# PCIE0_DAT register map
Vendor: Texas Instruments
Registers are 32-bit, read-write, reset 0x0 unless marked. A register's access mark holds for its fields unless they carry their own. Offsets are as the file gives them; [hi:lo] are bit positions; {n}, {i} and the like mark numbered series.

## PCIE0_DAT (part 2 of 6)
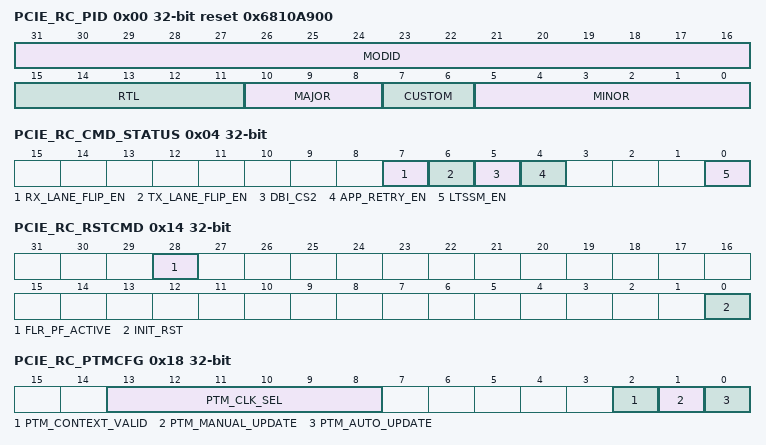
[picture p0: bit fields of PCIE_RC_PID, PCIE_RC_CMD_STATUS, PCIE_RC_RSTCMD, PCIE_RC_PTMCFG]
0x00 PCIE_RC_PID ro reset 0x6810A900 — Peripheral Version and ID Register
  [31:16] MODID — Module ID of the Peripheral
  [15:11] RTL — RTL Version Number
  [10:8] MAJOR — Major Revision Code
  [7:6] CUSTOM — Custom Code
  [5:0] MINOR — Minor Revision Code
0x04 PCIE_RC_CMD_STATUS access per field — Command Status Register
  [7] RX_LANE_FLIP_EN rw — Set to enable manual reversal for RX lanes. This drives the rx_lane_flip_en input of the PCIe core
  [6] TX_LANE_FLIP_EN rw — Set to enable manual reversal for TX lanes. This drives the tx_lane_flip_en input of the PCIe core
  [5] DBI_CS2 rw — Set to enable writing to BAR mask registers that are overlaid on BAR registers.
  [4] APP_RETRY_EN rw — Application Request Retry Enable. Setting this bit will enable all incoming PCIe transactions to be returned with a retry response. This feature can be used if initialization can take longer than PCIe stipulated time frame.
  [0] LTSSM_EN rw — Link Training Enable. Setting this bit will enable LTSSM in PCI Express Core and link negotiation with link partner will begin.
0x14 PCIE_RC_RSTCMD access not given — Reset Command and Status Register
  [28] FLR_PF_ACTIVE ro — Function-level reset for physical function active. 1 - FLR for Physical function 0 is active
  [0] INIT_RST — Write one to initiate a downstream hot reset sequence on downstream (access RW1S)
0x18 PCIE_RC_PTMCFG access not given — PTM Config register
  [13:8] PTM_CLK_SEL rw — Select ptm_local_clk bit input to CPTS. 0 will select ptm_local_clk[0], 1 will select ptm_local_clk[1] ... 63 will select ptm_local_clk[63]
  [2] PTM_CONTEXT_VALID ro — '1' indicates PTM context is valid-EP only
  [1] PTM_MANUAL_UPDATE — Write '1' to enable PTM transaction.EP only. EP will initiate one PTM transaction when this field is updated. Always reads '0' (access RW1S)
  [0] PTM_AUTO_UPDATE rw — Write '1' to enable PTM auto-update-EP only. EP will automatically initiate PTM transaction every 10ms
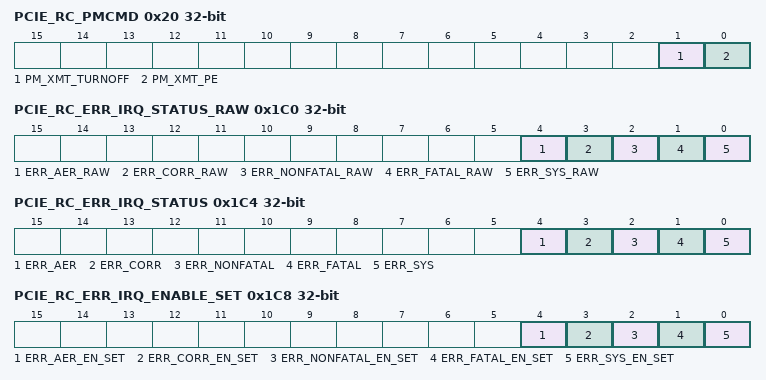
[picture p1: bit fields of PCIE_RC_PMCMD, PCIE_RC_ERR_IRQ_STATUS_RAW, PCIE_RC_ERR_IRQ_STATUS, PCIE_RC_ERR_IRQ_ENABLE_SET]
0x20 PCIE_RC_PMCMD access not given — Power Management Command Register
  [1] PM_XMT_TURNOFF — Write one to transmit a PM_TURNOFF message. Reads zero. Applicable in RC mode only. (access RW1S)
  [0] PM_XMT_PE — Write one to transmit a PM_PME message for Physical Function 0. Reads zero. Applicable to EP mode only. (access RW1S)
0x50 PCIE_RC_IRQ_EOI access per field — End of Interrupt Register
  [3:0] EOI rw — EOI for interrupts. Write to indicate end-of-interrupt for the respective interrupt. EOI value has to be the following as indicated below to toggle the interrupts in the various interrupt registers EOI = 0 for LEGACY_A_IRQ, EOI = 1 for LEGACY_B_IRQ, EOI = 2 for LEGACY_C_IRQ, EOI = 3 for LEGACY_D_IRQ, EOI = 4 for MMR0_IRQ, EOI = 5 for MMR1_IRQ, EOI = 6 for MMR2_IRQ, EOI = 7 for MMR3_IRQ, EOI = 8 for MMR4_IRQ, EOI = 9 for MMR5_IRQ, EOI = 10 for MMR6_IRQ, EOI = 11 for MMR7_IRQ, EOI = 12 for ERR_IRQ, EOI = 13 for PMRST_IRQ, EOI = 14 for PTM_IRQ
0x54 PCIE_RC_MMR_IRQ — Memory Mapped Interrupt IRQ Register
  [30:0] MMR_IRQ — This register is not used in RC mode.
0x64 PCIE_RC_LEGACY_IRQ_SET access not given — Legacy Interrupt Request Set Register
  [0] LEGACY_IRQ_SET_0 — Write one to generate assert legacy PCI interrupt message for Physical Function0. On read, a one indicates currently asserted interrupt. (access RW1S)
0x68 PCIE_RC_LEGACY_IRQ_CLR access not given — Legacy Interrupt Request Clear Register
  [0] LEGACY_IRQ_CLR_0 — Write one to generate legacy PCI deassert interrupt message for Physical Function0. If MSI is disabled, legacy interrupt deassert message will be generated. On read, a one indicates currently asserted interrupt. (access RW1C)
0x6C PCIE_RC_LEGACY_IRQ_STATUS ro — Legacy Interrupt Status Register
  [0] LEGACY_IRQ_STATUS_0 — Indicates whether legacy PCI interrupt for physical function 0 is asserted or not
{0x70+4i} PCIE_RC_GPR{i} (i=0..3) — General Purpose {i} Register
  [31:0] GENERIC{i} — Generic Info field {i}
{0x100+0x10*i} PCIE_RC_MMR{i}_IRQ_STATUS_RAW access not given (i=0..6) — MMR {i} Interrupt Raw Status Register
  [3:0] MMR{i}_IRQ_STATUS_RAW — Each bit indicates raw status of MMR vectors ({i+24}, {i+16}, {i+8}, {i}) associated with the bit. Typically, writes to this register are only done for debug purposes. (access RW1S)
{0x104+0x10*i} PCIE_RC_MMR{i}_IRQ_STATUS access not given (i=0..7) — MMR {i} Interrupt Status Register
  [3:0] MMR{i}_IRQ_STATUS — Each bit indicates status of MMR vector ({i+24}, {i+16}, {i+8}, {i}) associated with the bit. Each of the bits can be written with one to clear the respective interrupt status bit. (access RW1C)
{0x108+0x10*i} PCIE_RC_MMR{i}_IRQ_ENABLE_SET access not given (i=0..7) — MMR {i} Interrupt Enable Set Register
  [3:0] MMR{i}_IRQ_EN_SET — Each bit, when written to, enables the MMR interrupt ({i+24}, {i+16}, {i+8}, {i}) associated with the bit (access RW1S)
{0x10C+0x10*i} PCIE_RC_MMR{i}_IRQ_ENABLE_CLR access not given (i=0..7) — MMR {i} Interrupt Enable Clear Register
  [3:0] MMR{i}_IRQ_EN_CLR — Each bit, when written to, disables the MMR interrupt ({i+24}, {i+16}, {i+8}, {i}) associated with the bit (access RW1C)
0x170 PCIE_RC_MMR7_IRQ_STATUS_RAW access not given — MMR 7 Interrupt Raw Status Register
  [3:0] MMR7_IRQ_STATUS_RAW — (access RW1S)
0x180 PCIE_RC_LEGACY_A_IRQ_STATUS_RAW access not given — Legacy A Raw Interrupt Status Register
  [0] INTA_RAW — Legacy Interrupt A raw status. RC mode only (access RW1S)
0x184 PCIE_RC_LEGACY_A_IRQ_STATUS access not given — Legacy A Raw Interrupt Status Register
  [0] INTA — Legacy Interrupt A status. Set when interrupt is active. Write one to clear the interrupt event. RC mode only (access RW1C)
0x188 PCIE_RC_LEGACY_A_IRQ_ENABLE_SET access not given — Legacy A Interrupt Enable Set Register
  [0] INTA_EN_SET — Legacy Interrupt A enable. Set to enable the interrupt. On read, one/zero means interrupt is enabled/disabled. (access RW1S)
0x18C PCIE_RC_LEGACY_A_IRQ_ENABLE_CLR access not given — Legacy A Interrupt Enable Clear Register
  [0] INTA_EN_CLR — Legacy Interrupt A disable. Set to disable the interrupt. Read one/zero means interrupt is enabled/disabled. (access RW1C)
0x190 PCIE_RC_LEGACY_B_IRQ_STATUS_RAW access not given — Legacy B Raw Interrupt Status Register
  [0] INTB_RAW — Legacy Interrupt B raw status. RC mode only (access RW1S)
0x194 PCIE_RC_LEGACY_B_IRQ_STATUS access not given — Legacy B Interrupt Status Register
  [0] INTA — Legacy Interrupt B status. Set when interrupt is active. Write one to clear the interrupt event. RC mode only. (access RW1C)
0x198 PCIE_RC_LEGACY_B_IRQ_ENABLE_SET access not given — Legacy B Interrupt Enable Set Register
  [0] INTB_EN_SET — Legacy Interrupt B enable. Set to enable the interrupt. On read, one/zero means interrupt is enabled/disabled. (access RW1S)
0x19C PCIE_RC_LEGACY_B_IRQ_ENABLE_CLR access not given — Legacy B Interrupt Enable Clear Register
  [0] INTB_EN_CLR — Legacy Interrupt B disable. Set to disable the interrupt. Read one/zero means interrupt is enabled/disabled. (access RW1C)
0x1A0 PCIE_RC_LEGACY_C_IRQ_STATUS_RAW access not given — Legacy C Raw Interrupt Status Register
  [0] INTC_RAW — Legacy Interrupt C raw status. RC mode only (access RW1S)
0x1A4 PCIE_RC_LEGACY_C_IRQ_STATUS access not given — Legacy C Interrupt Status Register
  [0] INTA — Legacy Interrupt C status. Set when interrupt is active. Write one to clear the interrupt event. RC mode only (access RW1C)
0x1A8 PCIE_RC_LEGACY_C_IRQ_ENABLE_SET access not given — Legacy C Interrupt Enable Set Register
  [0] INTC_EN_SET — Legacy Interrupt C enable. Set to enable the interrupt. On read, one/zero means interrupt is enabled/disabled. (access RW1S)
0x1AC PCIE_RC_LEGACY_C_IRQ_ENABLE_CLR access not given — Legacy C Interrupt Enable Clear Register
  [0] INTC_EN_CLR — Legacy Interrupt C disable. Set to disable the interrupt. Read one/zero means interrupt is enabled/disabled. (access RW1C)
0x1B0 PCIE_RC_LEGACY_D_IRQ_STATUS_RAW access not given — Legacy D Raw Interrupt Status Register
  [0] INTD_RAW — Legacy Interrupt D raw status. RC mode only (access RW1S)
0x1B4 PCIE_RC_LEGACY_D_IRQ_STATUS access not given — Legacy D Interrupt Status Register
  [0] INTA — Legacy Interrupt D status. Set when interrupt is active. Write one to clear the interrupt event. RC mode only (access RW1C)
0x1B8 PCIE_RC_LEGACY_D_IRQ_ENABLE_SET access not given — Legacy D Interrupt Enable Set Register
  [0] INTD_EN_SET — Legacy Interrupt D enable. Set to enable the interrupt. On read, one/zero means interrupt is enabled/disabled. (access RW1S)
0x1BC PCIE_RC_LEGACY_D_IRQ_ENABLE_CLR access not given — Legacy D Interrupt Enable Clear Register
  [0] INTD_EN_CLR — Legacy Interrupt D disable. Set to disable the interrupt. Read one/zero means interrupt is enabled/disabled. (access RW1C)
0x1C0 PCIE_RC_ERR_IRQ_STATUS_RAW access not given — Raw ERR Interrupt Status Register
  [4] ERR_AER_RAW — AER MSI error raw status. This interrupt is generated due to the assertion of the cfg_aer_rc_err_int or the cfg_aer_err_msi output of the PCIe controller core. (access RW1S)
  [3] ERR_CORR_RAW — Correctable error raw status. This interrupt is generated due to the assertion of the radm_correctable_err output of the PCIe controller core. (access RW1S)
  [2] ERR_NONFATAL_RAW — Nonfatal error raw status. This interrupt is generated due to the assertion of the radm_nonfatal_err output of the PCIe controller core. (access RW1S)
  [1] ERR_FATAL_RAW — Fatal error raw status. This interrupt is generated due to the assertion of the radm_fatal_err output of the PCIe controller core. (access RW1S)
  [0] ERR_SYS_RAW — System Error (FATAL, NONFATAL or CORRECTABLE error) raw status. This interrupt is generated due to the assertion of the cfg_sys_err_rc output of the PCIe controller core. (access RW1S)
0x1C4 PCIE_RC_ERR_IRQ_STATUS access not given
  [4] ERR_AER — AER MSI error status. This interrupt is generated due to the assertion of the cfg_aer_rc_err_int or the cfg_aer_err_msi output of the PCIe controller core. Write one to clear (access RW1C)
  [3] ERR_CORR — Correctable error status. This interrupt is generated due to the assertion of the radm_correctable_err output of the PCIe controller core. Write one to clear (access RW1C)
  [2] ERR_NONFATAL — Nonfatal error status. This interrupt is generated due to the assertion of the radm_nonfatal_err output of the PCIe controller core. Write one to clear. (access RW1C)
  [1] ERR_FATAL — Fatal error status. This interrupt is generated due to the assertion of the radm_fatal_err output of the PCIe controller core. Write one to clear. (access RW1C)
  [0] ERR_SYS — System Error (FATAL, NONFATAL or CORRECTABLE error). This interrupt is generated due to the assertion of the cfg_sys_err_rc output of the PCIe controller core. Write one to clear. (access RW1C)
0x1C8 PCIE_RC_ERR_IRQ_ENABLE_SET access not given
  [4] ERR_AER_EN_SET — AER MSI error interrupt enable. Set to enable. On read, one/zero means enabled/disabled respectively (access RW1S)
  [3] ERR_CORR_EN_SET — Correctable error interrupt enable. Set to enable the interrupt. On read, one/zero means interrupt is enabled/disabled. (access RW1S)
  [2] ERR_NONFATAL_EN_SET — Nonfatal error interrupt enable. Set to enable the interrupt. On read, one/zero means interrupt is enabled/disabled. (access RW1S)
  [1] ERR_FATAL_EN_SET — Fatal error interrupt enable. Set to enable the interrupt. On read, one/zero means interrupt is enabled/disabled. (access RW1S)
  [0] ERR_SYS_EN_SET — System Error (FATAL, NONFATAL or CORRECTABLE error) interrupt enable. Set to enable the interrupt. On read, one/zero means interrupt is enabled/disabled. (access RW1S)
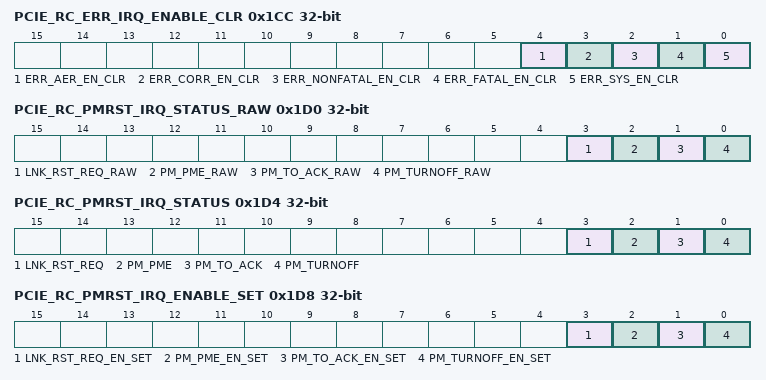
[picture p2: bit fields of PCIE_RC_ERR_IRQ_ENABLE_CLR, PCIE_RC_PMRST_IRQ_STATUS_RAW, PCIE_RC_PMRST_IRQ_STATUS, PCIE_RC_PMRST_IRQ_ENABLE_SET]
0x1CC PCIE_RC_ERR_IRQ_ENABLE_CLR access not given
  [4] ERR_AER_EN_CLR — AER MSI error interrupt disable. Set to disable. On read, one/zero means enabled/disabled respectively. (access RW1C)
  [3] ERR_CORR_EN_CLR — Correctable error interrupt disable. Set to disable the interrupt. Read one/zero means interrupt is enabled/disabled. (access RW1C)
  [2] ERR_NONFATAL_EN_CLR — Nonfatal error interrupt disable. Set to disable the interrupt. Read one/zero means interrupt is enabled/disabled. (access RW1C)
  [1] ERR_FATAL_EN_CLR — Fatal error interrupt disable. Set to disable the interrupt. Read one/zero means interrupt is enabled/disabled. (access RW1C)
  [0] ERR_SYS_EN_CLR — System Error (FATAL, NONFATAL or CORRECTABLE error) interrupt disable. Set to disable the interrupt. Read one/zero means interrupt is enabled/disabled. (access RW1C)
0x1D0 PCIE_RC_PMRST_IRQ_STATUS_RAW access not given — Power Management and Reset Interrupt Raw Status Register
  [3] LNK_RST_REQ_RAW — Link Request Reset interrupt raw status (access RW1S)
  [2] PM_PME_RAW — Power Management PME message received interrupt raw status (access RW1S)
  [1] PM_TO_ACK_RAW — Power Management ACK received interrupt raw status (access RW1S)
  [0] PM_TURNOFF_RAW — Power Management Turnoff message received raw status (access RW1S)
0x1D4 PCIE_RC_PMRST_IRQ_STATUS access not given — Power Management and Reset Interrupt Status Register
  [3] LNK_RST_REQ — Link Request Reset interrupt status. Write one to clear (access RW1C)
  [2] PM_PME — Power Management PME message received interrupt status. Write one to clear. (access RW1C)
  [1] PM_TO_ACK — Power Management ACK received interrupt status. Write one to clear. (access RW1C)
  [0] PM_TURNOFF — Power Management Turnoff message received status. Write one to clear. (access RW1C)
0x1D8 PCIE_RC_PMRST_IRQ_ENABLE_SET access not given — Power Management and Reset Interrupt Enable Set Register
  [3] LNK_RST_REQ_EN_SET — Link Request Reset interrupt enable. Set to enable the interrupt. Read one/zero means interrupt is enabled/disabled. (access RW1S)
  [2] PM_PME_EN_SET — Power Management PME message received interrupt enable. Set to enable the interrupt. Read one/zero means interrupt is enabled/disabled. (access RW1S)
  [1] PM_TO_ACK_EN_SET — Power Management ACK received interrupt enable. Set to enable the interrupt. Read one/zero means interrupt is enabled/disabled. (access RW1S)
  [0] PM_TURNOFF_EN_SET — Power Management Turnoff message received enable. Set to enable the interrupt. Read one/zero means interrupt is enabled/disabled. (access RW1S)
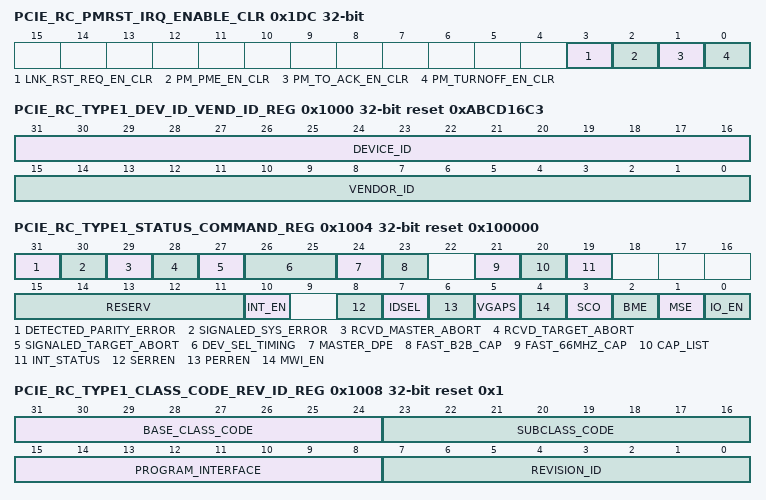
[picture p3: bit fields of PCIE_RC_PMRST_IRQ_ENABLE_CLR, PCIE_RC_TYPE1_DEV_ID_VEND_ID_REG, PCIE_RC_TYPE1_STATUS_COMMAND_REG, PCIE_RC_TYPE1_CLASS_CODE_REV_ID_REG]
0x1DC PCIE_RC_PMRST_IRQ_ENABLE_CLR access not given — Power Management and Reset Interrupt Enable Clear Register
  [3] LNK_RST_REQ_EN_CLR — Link Request Reset interrupt disable. Set to disable the interrupt. Read one/zero means interrupt is enabled/disabled. (access RW1C)
  [2] PM_PME_EN_CLR — Power Management PME message received interrupt disable. Set to disable the interrupt. Read one/zero means interrupt is enabled/disabled. (access RW1C)
  [1] PM_TO_ACK_EN_CLR — Power Management ACK received interrupt disable. Set to disable the interrupt. Read one/zero means interrupt is enabled/disabled. (access RW1C)
  [0] PM_TURNOFF_EN_CLR — Power Management Turnoff message received disable. Set to disable the interrupt. Read one/zero means interrupt is enabled/disabled (access RW1C)
0x1E0 PCIE_RC_PTM_IRQ_STATUS_RAW access not given — Precision Time Measurement Raw Status Register
  [0] PTM_CLK_UPDATED_RAW — Precision Time Measurement interrupt raw status (access RW1S)
0x1E4 PCIE_RC_PTM_IRQ_STATUS access not given — Precision Time Measurement Status Register
  [0] PTM_CLK_UPDATED — Precision Time Measurement interrupt status (access RW1C)
0x1E8 PCIE_RC_PTM_IRQ_ENABLE_SET access not given — Precision Time Measurement Enable Set Register
  [0] PTM_CLK_UPDATED_EN_SET — Precision Time Measurement interrupt enable set. Write one to set (access RW1S)
0x1EC PCIE_RC_PTM_IRQ_ENABLE_CLR access not given — Precision Time Measurement Enable Clear Register
  [0] PTM_CLK_UPDATED_EN_CLR — Precision Time Measurement interrupt enable clear. Write one to clear (access RW1C)
0x1000 PCIE_RC_TYPE1_DEV_ID_VEND_ID_REG ro reset 0xABCD16C3 — Device ID and Vendor ID Register. For a description of this standard PCIe register, see the PCI Express Specification.
  [31:16] DEVICE_ID — Device ID - Vendor Assigned Device Identifier For a description of this standard PCIe register field, see the PCI Express Specification Note: The access attributes of this field are as follows: - Dbi: if [DBI_RO_WR_EN == 1] then R/W[sticky] else R[sticky] Note: This register field is sticky
  [15:0] VENDOR_ID — Vendor ID - PCI-SIG assigned Manufacturer Identifier For a description of this standard PCIe register field, see the PCI Express Specification Note: The access attributes of this field are as follows: - Dbi: if [DBI_RO_WR_EN == 1] then R/W[sticky] else R[sticky] Note: This register field is sticky
0x1004 PCIE_RC_TYPE1_STATUS_COMMAND_REG access not given reset 0x100000 — Command and Status Register. For a description of this standard PCIe register, see the PCI Express Specification.
  [31] DETECTED_PARITY_ERROR — Poisoned TLP received by function on Primary Side For a description of this standard PCIe register field, see the PCI Express Specification (access RW1C)
  [30] SIGNALED_SYS_ERROR — Fatal or Non-Fatal Error Message sent by function For a description of this standard PCIe register field, see the PCI Express Specification (access RW1C)
  [29] RCVD_MASTER_ABORT — Unsupported request completion status received on Primary Side For a description of this standard PCIe register field, see the PCI Express Specification (access RW1C)
  [28] RCVD_TARGET_ABORT — Completer Abort received on Primary Side For a description of this standard PCIe register field, see the PCI Express Specification (access RW1C)
  [27] SIGNALED_TARGET_ABORT — Primary Side Completer Abort Error For a description of this standard PCIe register field, see the PCI Express Specification (access RW1C)
  [26:25] DEV_SEL_TIMING ro — Device Select Timing For a description of this standard PCIe register field, see the PCI Express Specification
  [24] MASTER_DPE — Controls poisoned Completion and Request error reporting For a description of this standard PCIe register field, see the PCI Express Specification (access RW1C)
  [23] FAST_B2B_CAP ro — Fast Back to Back Transaction Capable and Enable For a description of this standard PCIe register field, see the PCI Express Specification
  [21] FAST_66MHZ_CAP ro — PCI 66MHz Capability For a description of this standard PCIe register field, see the PCI Express Specification
  [20] CAP_LIST ro — Extended Capability For a description of this standard PCIe register field, see the PCI Express Specification
  [19] INT_STATUS ro — Emulation interrupt pending internally in function For a description of this standard PCIe register field, see the PCI Express Specification
  [15:11] RESERV ro — Reserved For a description of this standard PCIe register field, see the PCI Express Specification
  [10] INT_EN rw — Interrupt Disable Controls generation of interrupts by an internal function For a description of this standard PCIe register field, see the PCI Express Specification
  [8] SERREN rw — Enables Error Reporting and Forwarding For a description of this standard PCIe register field, see the PCI Express Specification
  [7] IDSEL ro — IDSEL Stepping/Wait Cycle Control For a description of this standard PCIe register field, see the PCI Express Specification
  [6] PERREN rw — Parity Error Response Controls Logging of Poisoned TLPs For a description of this standard PCIe register field, see the PCI Express Specification
  [5] VGAPS ro — VGA Palette Snoop For a description of this standard PCIe register field, see the PCI Express Specification
  [4] MWI_EN ro — Memory Write and Invalidate For a description of this standard PCIe register field, see the PCI Express Specification
  [3] SCO ro — Special Cycle Enable For a description of this standard PCIe register field, see the PCI Express Specification
  [2] BME rw — Bus Master Enable Controls Forwarding of Memory and I/O Requests For a description of this standard PCIe register field, see the PCI Express Specification
  [1] MSE rw — Enables Memory Access Response For a description of this standard PCIe register field, see the PCI Express Specification You cannot write to this register if your configuration has no MEM bars that is, the internal signal has_mem_bar=0 Note: The access attributes of this field are as follows: - Dbi: !has_mem_bar ? RO : RW
  [0] IO_EN rw — Enables IO Access Response For a description of this standard PCIe register field, see the PCI Express Specification You cannot write to this register if your configuration has no IO bars that is, the internal signal has_io_bar=0 Note: The access attributes of this field are as follows: - Dbi: !has_io_bar ? RO : RW
0x1008 PCIE_RC_TYPE1_CLASS_CODE_REV_ID_REG ro reset 0x1 — Class Code and Revision ID Register. For a description of this standard PCIe register, see the PCI Express Specification.
  [31:24] BASE_CLASS_CODE — Base Class Code to represent Device Type For a description of this standard PCIe register field, see the PCI Express Specification Note: The access attributes of this field are as follows: - Dbi: if [DBI_RO_WR_EN == 1] then R/W[sticky] else R[sticky] Note: This register field is sticky
  [23:16] SUBCLASS_CODE — Subclass Code to represent Device Type For a description of this standard PCIe register field, see the PCI Express Specification Note: The access attributes of this field are as follows: - Dbi: if [DBI_RO_WR_EN == 1] then R/W[sticky] else R[sticky] Note: This register field is sticky
  [15:8] PROGRAM_INTERFACE — Class Code Programming Interface For a description of this standard PCIe register field, see the PCI Express Specification Note: The access attributes of this field are as follows: - Dbi: if [DBI_RO_WR_EN == 1] then R/W[sticky] else R[sticky] Note: This register field is sticky
  [7:0] REVISION_ID — Vendor chosen Revision ID For a description of this standard PCIe register field, see the PCI Express Specification Note: The access attributes of this field are as follows: - Dbi: if [DBI_RO_WR_EN == 1] then R/W[sticky] else R[sticky] Note: This register field is sticky
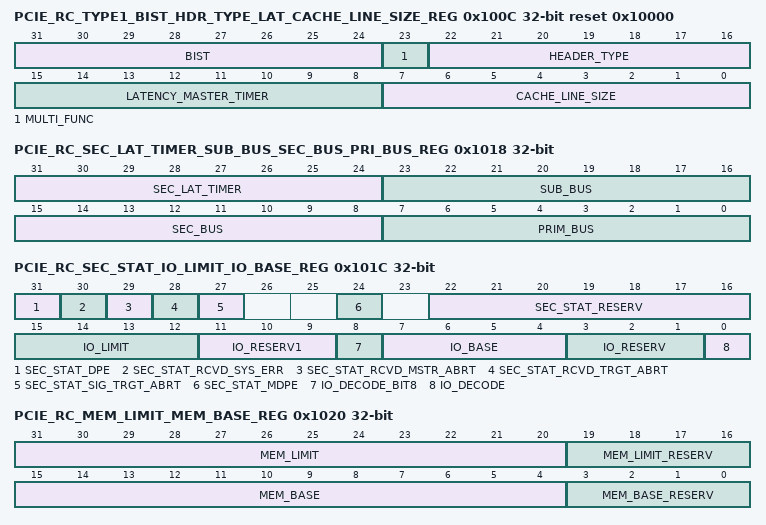
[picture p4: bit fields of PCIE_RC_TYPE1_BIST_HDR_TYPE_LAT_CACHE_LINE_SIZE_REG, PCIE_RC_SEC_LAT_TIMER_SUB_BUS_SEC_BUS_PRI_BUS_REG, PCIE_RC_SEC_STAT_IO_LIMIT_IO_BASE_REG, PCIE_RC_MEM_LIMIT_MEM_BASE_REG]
0x100C PCIE_RC_TYPE1_BIST_HDR_TYPE_LAT_CACHE_LINE_SIZE_REG access per field reset 0x10000 — BIST, Header Type, Cache Line Size, and Master Latency Timer Register. For a description of this standard PCIe register, see the PCI Express Specification.
  [31:24] BIST ro — Optional for BIST support For a description of this standard PCIe register field, see the PCI Express Specification
  [23] MULTI_FUNC ro — Specifies whether device is multifunction For a description of this standard PCIe register field, see the PCI Express Specification Note: This register field is sticky
  [22:16] HEADER_TYPE ro — Specifies Header Type For a description of this standard PCIe register field, see the PCI Express Specification
  [15:8] LATENCY_MASTER_TIMER ro — Primary Latency Timer Does not apply to PCI Express For a description of this standard PCIe register field, see the PCI Express Specification
  [7:0] CACHE_LINE_SIZE rw — Cache Line Size field Has no effect on PCIe device behavior For a description of this standard PCIe register field, see the PCI Express Specification
0x1018 PCIE_RC_SEC_LAT_TIMER_SUB_BUS_SEC_BUS_PRI_BUS_REG access per field — Primary, Secondary, Subordinate Bus Numbers and Latency Timer Registers. For a description of this standard PCIe register, see the PCI Express Specification.
  [31:24] SEC_LAT_TIMER ro — Latency Timer Not used in PCI-Express For a description of this standard PCIe register field, see the PCI Express Specification
  [23:16] SUB_BUS rw — Subordinate Bus Number Not used in PCI-Express For a description of this standard PCIe register field, see the PCI Express Specification
  [15:8] SEC_BUS rw — Secondary Bus Number Not used in PCI-Express For a description of this standard PCIe register field, see the PCI Express Specification
  [7:0] PRIM_BUS rw — Primary Bus Number Not used in PCI-Express For a description of this standard PCIe register field, see the PCI Express Specification
0x101C PCIE_RC_SEC_STAT_IO_LIMIT_IO_BASE_REG access not given — Secondary Status and I/O Base and Limit Registers. For a description of this standard PCIe register, see the PCI Express Specification.
  [31] SEC_STAT_DPE — Detected Parity Error Poisoned TLP Received on Secondary Side For a description of this standard PCIe register field, see the PCI Express Specification (access RW1C)
  [30] SEC_STAT_RCVD_SYS_ERR — Received System Error Fatal or non-fatal error received For a description of this standard PCIe register field, see the PCI Express Specification (access RW1C)
  [29] SEC_STAT_RCVD_MSTR_ABRT — Received Master Abort, secondary side For a description of this standard PCIe register field, see the PCI Express Specification (access RW1C)
  [28] SEC_STAT_RCVD_TRGT_ABRT — Received Target Abort, secondary side For a description of this standard PCIe register field, see the PCI Express Specification (access RW1C)
  [27] SEC_STAT_SIG_TRGT_ABRT — Signaled Target Abort, secondary side For a description of this standard PCIe register field, see the PCI Express Specification (access RW1C)
  [24] SEC_STAT_MDPE — Master Data Parity Error For a description of this standard PCIe register field, see the PCI Express Specification (access RW1C)
  [22:16] SEC_STAT_RESERV ro — Reserved For a description of this standard PCIe register field, see the PCI Express Specification
  [15:12] IO_LIMIT rw — I/O Limit Address For a description of this standard PCIe register field, see the PCI Express Specification
  [11:9] IO_RESERV1 ro — Reserved For a description of this standard PCIe register field, see the PCI Express Specification
  [8] IO_DECODE_BIT8 ro — I/O 8-bit Decode For a description of this standard PCIe register field, see the PCI Express Specification Note: The access attributes of this field are as follows: - Dbi: R
  [7:4] IO_BASE rw — I/O Base Address For a description of this standard PCIe register field, see the PCI Express Specification
  [3:1] IO_RESERV ro — Reserved For a description of this standard PCIe register field, see the PCI Express Specification
  [0] IO_DECODE ro — I/O Decode For a description of this standard PCIe register field, see the PCI Express Specification Note: The access attributes of this field are as follows: - Dbi: if [DBI_RO_WR_EN == 1] then R/W else R
0x1020 PCIE_RC_MEM_LIMIT_MEM_BASE_REG access per field — Memory Base and Memory Limit Register. For a description of this standard PCIe register, see the PCI Express Specification.
  [31:20] MEM_LIMIT rw — Memory Limit Address For a description of this standard PCIe register field, see the PCI Express Specification
  [19:16] MEM_LIMIT_RESERV ro — Reserved For a description of this standard PCIe register field, see the PCI Express Specification
  [15:4] MEM_BASE rw — Memory Base Address For a description of this standard PCIe register field, see the PCI Express Specification
  [3:0] MEM_BASE_RESERV ro — Reserved For a description of this standard PCIe register field, see the PCI Express Specification
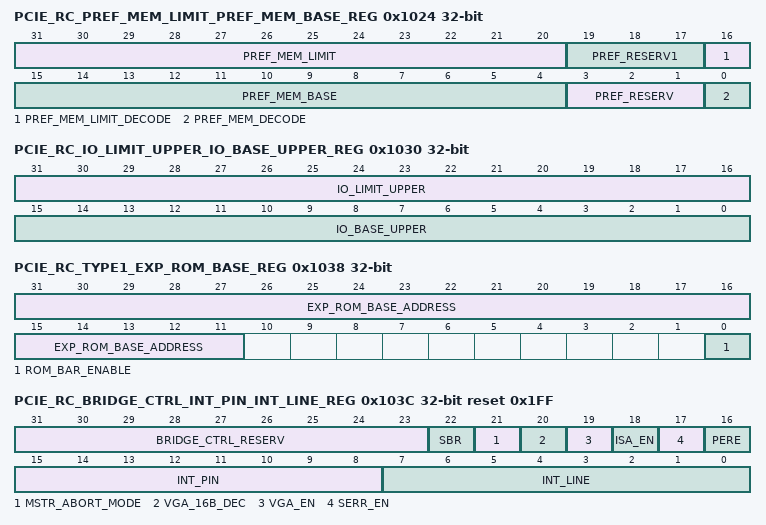
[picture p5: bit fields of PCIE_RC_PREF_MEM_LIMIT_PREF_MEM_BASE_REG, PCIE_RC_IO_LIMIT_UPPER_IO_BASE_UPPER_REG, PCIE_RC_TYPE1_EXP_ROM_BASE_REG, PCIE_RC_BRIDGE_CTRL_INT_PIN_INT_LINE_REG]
0x1024 PCIE_RC_PREF_MEM_LIMIT_PREF_MEM_BASE_REG access per field — Prefetchable Memory Base and Limit Register. For a description of this standard PCIe register, see the PCI Express Specification.
  [31:20] PREF_MEM_LIMIT rw — Prefetchable Memory Limit Address For a description of this standard PCIe register field, see the PCI Express Specification
  [19:17] PREF_RESERV1 ro — Reserved For a description of this standard PCIe register field, see the PCI Express Specification
  [16] PREF_MEM_LIMIT_DECODE ro — Prefetchable Memory Limit Decode For a description of this standard PCIe register field, see the PCI Express Specification
  [15:4] PREF_MEM_BASE rw — Prefetchable Memory Base Address For a description of this standard PCIe register field, see the PCI Express Specification
  [3:1] PREF_RESERV ro — Reserved For a description of this standard PCIe register field, see the PCI Express Specification
  [0] PREF_MEM_DECODE ro — Prefetchable Memory Decode For a description of this standard PCIe register field, see the PCI Express Specification Note: The access attributes of this field are as follows: - Dbi: if [DBI_RO_WR_EN == 1] then R/W else R Note: This register field is sticky
0x1028 PCIE_RC_PREF_BASE_UPPER_REG ro — Prefetchable Base Upper 32 Bits Register. For a description of this standard PCIe register, see the PCI Express Specification.
  [31:0] PREF_MEM_BASE_UPPER — Prefetchable Memory Base Upper Address For a description of this standard PCIe register field, see the PCI Express Specification Note: The access attributes of this field are as follows: - Dbi: if [DBI_RO_WR_EN == 1] then R/W else R
0x102C PCIE_RC_PREF_LIMIT_UPPER_REG ro — Prefetchable Limit Upper 32 Bits Register. For a description of this standard PCIe register, see the PCI Express Specification.
  [31:0] PREF_MEM_LIMIT_UPPER — Prefetchable Memory Limit Upper Address For a description of this standard PCIe register field, see the PCI Express Specification Note: The access attributes of this field are as follows: - Dbi: if [DBI_RO_WR_EN == 1] then R/W else R
0x1030 PCIE_RC_IO_LIMIT_UPPER_IO_BASE_UPPER_REG ro — I/O Base and Limit Upper 16 Bits Register. For a description of this standard PCIe register, see the PCI Express Specification.
  [31:16] IO_LIMIT_UPPER — Prefetchable I/O Limit Upper Address For a description of this standard PCIe register field, see the PCI Express Specification Note: The access attributes of this field are as follows: - Dbi: if [DBI_RO_WR_EN == 1] then R/W else R
  [15:0] IO_BASE_UPPER — Prefetchable I/O Base Upper Address For a description of this standard PCIe register field, see the PCI Express Specification Note: The access attributes of this field are as follows: - Dbi: if [DBI_RO_WR_EN == 1] then R/W else R
0x1034 PCIE_RC_TYPE1_CAP_PTR_REG ro reset 0x40 — Capability Pointer Register. For a description of this standard PCIe register, see the PCI Express Specification.
  [7:0] CAP_POINTER — Pointer to first item in the PCI Capability Structure For a description of this standard PCIe register field, see the PCI Express Specification Note: The access attributes of this field are as follows: - Dbi: if [DBI_RO_WR_EN == 1] then R/W[sticky] else R[sticky] Note: This register field is sticky
0x1038 PCIE_RC_TYPE1_EXP_ROM_BASE_REG access per field — Expansion ROM BAR and Mask Register. For a description of this standard PCIe register, see the PCI Express Specification. The mask for this ROM BAR exists (if implemented) as a shadow register at this address. The assertion of CS2 (that is, assert the dbi_cs2 input, or the CS2 address bit for the AXI bridge) is required to write to the second register at this address.
  [31:11] EXP_ROM_BASE_ADDRESS rw — Expansion ROM BAR and Mask Register For a description of this standard PCIe register, see the PCI Express Specification The mask for this ROM BAR exists [if implemented] as a shadow register at this address The assertion of CS2 [that is, assert the dbi_cs2 input, or the CS2 address bit for the AXI bridge] is required to write to the second register at this address Note: The access attributes of this field are as follows: - Dbi: R/W
  [0] ROM_BAR_ENABLE rw — Expansion ROM Enable For a description of this standard PCIe register field, see the PCI Express Specification Note: The access attributes of this field are as follows: - Dbi: R/W
0x103C PCIE_RC_BRIDGE_CTRL_INT_PIN_INT_LINE_REG access per field reset 0x1FF — Interrupt Line and Pin and Bridge Control Registers. For a description of this standard PCIe register, see the PCI Express Specification.
  [31:23] BRIDGE_CTRL_RESERV ro — Reserved For a description of this standard PCIe register field, see the PCI Express Specification
  [22] SBR rw — Secondary Bus Hot Reset For a description of this standard PCIe register field, see the PCI Express Specification
  [21] MSTR_ABORT_MODE ro — Master Abort Mode Does not apply to PCI Express For a description of this standard PCIe register field, see the PCI Express Specification Note: The access attributes of this field are as follows: - Dbi: R/W
  [20] VGA_16B_DEC ro — VGA 16 bit decode For a description of this standard PCIe register field, see the PCI Express Specification Note: The access attributes of this field are as follows: - Dbi: R
  [19] VGA_EN ro — VGA Enable For a description of this standard PCIe register field, see the PCI Express Specification Note: The access attributes of this field are as follows: - Dbi: R
  [18] ISA_EN rw — ISA Enable For a description of this standard PCIe register field, see the PCI Express Specification
  [17] SERR_EN rw — System Error Response Enable from Secondary to Primary For a description of this standard PCIe register field, see the PCI Express Specification
  [16] PERE rw — Parity Error Response Enable Controls Logging of Poisoned TLPs For a description of this standard PCIe register field, see the PCI Express Specification
  [15:8] INT_PIN ro — PCI Compatible Interrupt Pin Register Field For a description of this standard PCIe register field, see the PCI Express Specification Note: The access attributes of this field are as follows: - Dbi: if [DBI_RO_WR_EN == 1] then R/W else R Note: This register field is sticky
  [7:0] INT_LINE rw — PCI Compatible Interrupt Line Routing Register Field For a description of this standard PCIe register field, see the PCI Express Specification
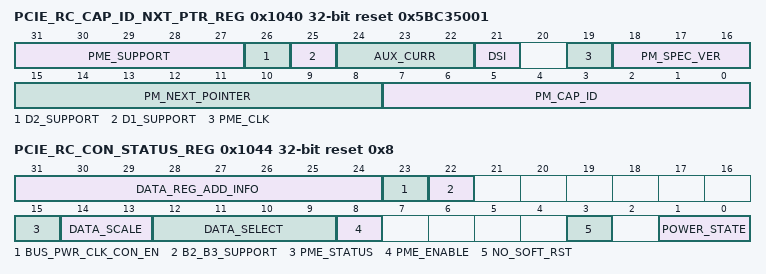
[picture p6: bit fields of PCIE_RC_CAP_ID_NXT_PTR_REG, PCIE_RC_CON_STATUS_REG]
0x1040 PCIE_RC_CAP_ID_NXT_PTR_REG ro reset 0x5BC35001 — Power Management Capabilities Register. For a description of this standard PCIe register, see the PCI Express Specification.
  [31:27] PME_SUPPORT — Power Management Event Support For a description of this standard PCIe register field, see the PCI Express Specification The read value from this field is the write value &amp;&amp; [sys_aux_pwr_det, 1'b1, D2_SUPPORT, D1_SUPPORT, 1'b1], where D1_SUPPORT and D2_SUPPORT are fields in this register The reset value PME_SUPPORT_n &amp;&amp; [sys_aux_pwr_det, 1'b1, D2_SUPPORT, D1_SUPPORT, 1'b1], where PME_SUPPORT_n is a configuration parameter Note: The access attributes of this field are as follows: - Dbi: if [DBI_RO_WR_EN == 1] then R/W else R Note: This register field is sticky
  [26] D2_SUPPORT — D2 State Support For a description of this standard PCIe register field, see the PCI Express Specification Note: The access attributes of this field are as follows: - Dbi: if [DBI_RO_WR_EN == 1] then R/W else R Note: This register field is sticky
  [25] D1_SUPPORT — D1 State Support For a description of this standard PCIe register field, see the PCI Express Specification Note: The access attributes of this field are as follows: - Dbi: if [DBI_RO_WR_EN == 1] then R/W else R Note: This register field is sticky
  [24:22] AUX_CURR — Auxiliary Current Requirements For a description of this standard PCIe register field, see the PCI Express Specification Note: The access attributes of this field are as follows: - Dbi: if [DBI_RO_WR_EN == 1] then R/W else R Note: This register field is sticky
  [21] DSI — Device Specific Initialization Bit For a description of this standard PCIe register field, see the PCI Express Specification Note: The access attributes of this field are as follows: - Dbi: if [DBI_RO_WR_EN == 1] then R/W else R Note: This register field is sticky
  [19] PME_CLK — PCI Clock Requirement For a description of this standard PCIe register field, see the PCI Express Specification Note: This register field is sticky
  [18:16] PM_SPEC_VER — Power Management Spec Version For a description of this standard PCIe register field, see the PCI Express Specification Note: The access attributes of this field are as follows: - Dbi: if [DBI_RO_WR_EN == 1] then R/W else R Note: This register field is sticky
  [15:8] PM_NEXT_POINTER — Next Capability Pointer For a description of this standard PCIe register field, see the PCI Express Specification Note: The access attributes of this field are as follows: - Dbi: if [DBI_RO_WR_EN == 1] then R/W else R Note: This register field is sticky
  [7:0] PM_CAP_ID — Power Management Capability ID For a description of this standard PCIe register field, see the PCI Express Specification
0x1044 PCIE_RC_CON_STATUS_REG access not given reset 0x8 — Power Management Control and Status Register. For a description of this standard PCIe register, see the PCI Express Specification.
  [31:24] DATA_REG_ADD_INFO ro — Power Data Information Register For a description of this standard PCIe register field, see the PCI Express Specification
  [23] BUS_PWR_CLK_CON_EN ro — Bus Power/Clock Control Enable For a description of this standard PCIe register field, see the PCI Express Specification
  [22] B2_B3_SUPPORT ro — B2B3 Support for D3hot For a description of this standard PCIe register field, see the PCI Express Specification
  [15] PME_STATUS — PME Status For a description of this standard PCIe register field, see the PCI Express Specification (access RW1C)
  [14:13] DATA_SCALE ro — Data Scaling Factor For a description of this standard PCIe register field, see the PCI Express Specification
  [12:9] DATA_SELECT ro — Data Select For a description of this standard PCIe register field, see the PCI Express Specification
  [8] PME_ENABLE rw — PME Enable For a description of this standard PCIe register field, see the PCI Express Specification The PMC registers this value under aux power Sometimes it might remember the old value, even if you try to clear it by writing '0' Note: This register field is sticky
  [3] NO_SOFT_RST ro — No soft Reset For a description of this standard PCIe register field, see the PCI Express Specification Note: The access attributes of this field are as follows: - Dbi: if [DBI_RO_WR_EN == 1] then R/W else R Note: This register field is sticky
  [1:0] POWER_STATE rw — Power State For a description of this standard PCIe register field, see the PCI Express Specification You can write to this register However, the read-back value is the actual power state, not the write value Note: The access attributes of this field are as follows: - Dbi: R/W
